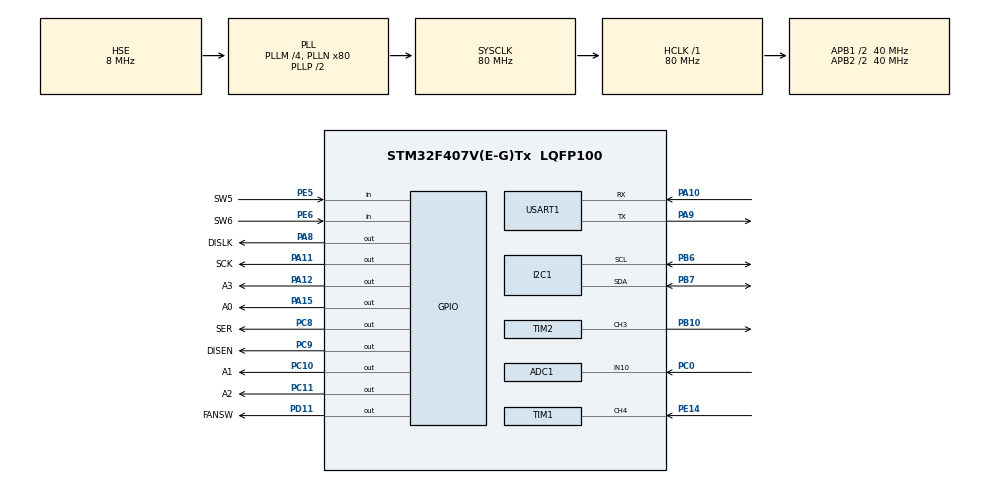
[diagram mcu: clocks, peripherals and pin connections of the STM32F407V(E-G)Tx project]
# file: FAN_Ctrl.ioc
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ADC1.Channel-1\#ChannelRegularConversion=ADC_CHANNEL_10
ADC1.ClockPrescaler=ADC_CLOCK_SYNC_PCLK_DIV2
ADC1.ContinuousConvMode=ENABLE
ADC1.NbrOfConversionFlag=1
ADC1.Rank-1\#ChannelRegularConversion=1
ADC1.Resolution=ADC_RESOLUTION_12B
ADC1.SamplingTime-1\#ChannelRegularConversion=ADC_SAMPLETIME_3CYCLES
ADC1.master=1
Mcu.Family=STM32F4
Mcu.Name=STM32F407V(E-G)Tx
Mcu.Package=LQFP100
NVIC.ADC_IRQn=true\:0\:0\:false\:false\:true\:true\:true\:true
NVIC.PriorityGroup=NVIC_PRIORITYGROUP_4
NVIC.TIM1_CC_IRQn=true\:0\:0\:false\:false\:true\:true\:true\:true
NVIC.TIM2_IRQn=true\:0\:0\:false\:false\:true\:true\:true\:true
NVIC.TIM6_DAC_IRQn=true\:0\:0\:false\:false\:true\:true\:true\:true
NVIC.USART1_IRQn=true\:0\:0\:false\:false\:true\:true\:true\:true
PA10.Mode=Asynchronous
PA10.Signal=USART1_RX
PA11.GPIO_Label=SCK
PA11.Signal=GPIO_Output
PA12.GPIO_Label=A3
PA12.Signal=GPIO_Output
PA13.Mode=Serial_Wire
PA13.Signal=SYS_JTMS-SWDIO
PA14.Mode=Serial_Wire
PA14.Signal=SYS_JTCK-SWCLK
PA15.GPIO_Label=A0
PA15.Signal=GPIO_Output
PA8.GPIO_Label=DISLK
PA8.Signal=GPIO_Output
PA9.Mode=Asynchronous
PA9.Signal=USART1_TX
PB10.Signal=S_TIM2_CH3
PB6.Mode=I2C
PB6.Signal=I2C1_SCL
PB7.Mode=I2C
PB7.Signal=I2C1_SDA
PC0.Signal=SharedAnalog_PC0
PC10.GPIO_Label=A1
PC10.Signal=GPIO_Output
PC11.GPIO_Label=A2
PC11.Signal=GPIO_Output
PC8.GPIO_Label=SER
PC8.Signal=GPIO_Output
PC9.GPIO_Label=DISEN
PC9.Signal=GPIO_Output
PD11.GPIO_Label=FANSW
PD11.Signal=GPIO_Output
PE14.GPIO_PuPd=GPIO_PULLUP
PE14.GPIO_Speed=GPIO_SPEED_FREQ_HIGH
PE14.Signal=S_TIM1_CH4
PE5.GPIO_Label=SW5
PE5.Signal=GPIO_Input
PE6.GPIO_Label=SW6
PE6.Signal=GPIO_Input
PH0-OSC_IN.Mode=HSE-External-Oscillator
PH0-OSC_IN.Signal=RCC_OSC_IN
PH1-OSC_OUT.Mode=HSE-External-Oscillator
PH1-OSC_OUT.Signal=RCC_OSC_OUT
ProjectManager.HeapSize=0x200
ProjectManager.StackSize=0x400
ProjectManager.TargetToolchain=MDK-ARM V5.32
RCC.48MHZClocksFreq_Value=40000000
RCC.AHBFreq_Value=80000000
RCC.APB1CLKDivider=RCC_HCLK_DIV2
RCC.APB1Freq_Value=40000000
RCC.APB1TimFreq_Value=80000000
RCC.APB2CLKDivider=RCC_HCLK_DIV2
RCC.APB2Freq_Value=40000000
RCC.APB2TimFreq_Value=80000000
RCC.CortexFreq_Value=80000000
RCC.EnbaleCSS=true
RCC.HCLKFreq_Value=80000000
RCC.HSE_VALUE=8000000
RCC.HSI_VALUE=16000000
RCC.LSE_VALUE=32768
RCC.PLLM=4
RCC.PLLN=80
RCC.PLLSourceVirtual=RCC_PLLSOURCE_HSE
RCC.SYSCLKFreq_VALUE=80000000
RCC.SYSCLKSource=RCC_SYSCLKSOURCE_PLLCLK
RCC.VCOOutputFreq_Value=160000000
SH.S_TIM1_CH4.0=TIM1_CH4,Input_Capture4_from_TI4
SH.S_TIM2_CH3.0=TIM2_CH3,PWM Generation3 CH3
SH.SharedAnalog_PC0.0=GPIO_Analog
SH.SharedAnalog_PC0.1=ADC1_IN10,IN10
TIM1.Channel-Input_Capture4_from_TI4=TIM_CHANNEL_4
TIM1.Prescaler=80-1
TIM2.Channel-PWM\ Generation3\ CH3=TIM_CHANNEL_3
TIM2.Period=100-1
TIM2.Prescaler=80-1
TIM2.Pulse-PWM\ Generation3\ CH3=50
TIM6.Period=1000-1
TIM6.Prescaler=80-1
USART1.VirtualMode=VM_ASYNC
VP_TIM1_VS_ClockSourceINT.Mode=Internal
VP_TIM2_VS_ClockSourceINT.Mode=Internal
VP_TIM6_VS_ClockSourceINT.Mode=Enable_Timer
board=custom

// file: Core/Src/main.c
/* USER CODE BEGIN Header */
/**
  ******************************************************************************
  * @file           : main.c
  * @brief          : Main program body
  ******************************************************************************
  * @attention
  *
  * Copyright (c) 2025 STMicroelectronics.
  * All rights reserved.
  *
  * This software is licensed under terms that can be found in the LICENSE file
  * in the root directory of this software component.
  * If no LICENSE file comes with this software, it is provided AS-IS.
  *
  ******************************************************************************
  */
/* USER CODE END Header */
#include "main.h"
#include "adc.h"
#include "i2c.h"
#include "tim.h"
#include "usart.h"
#include "gpio.h"

/* USER CODE BEGIN Includes */
#include "app.h"
/* USER CODE END Includes */

/* USER CODE BEGIN PTD */

/* USER CODE BEGIN PTD */

/* USER CODE END PTD */

void SystemClock_Config(void);

int main(void)
{

  /* MCU Configuration--------------------------------------------------------*/

  /* Reset of all peripherals, Initializes the Flash interface and the Systick. */
  HAL_Init();

  /* Configure the system clock */
  SystemClock_Config();

  /* Initialize all configured peripherals */
  MX_GPIO_Init();
  MX_TIM2_Init();
  MX_ADC1_Init();
  MX_USART1_UART_Init();
  MX_TIM1_Init();
  MX_I2C1_Init();
  MX_TIM6_Init();

  /* Infinite loop */
  while (1)
  {

    /* USER CODE BEGIN 3 */
		app_main();
  }
  /* USER CODE END 3 */
}

void SystemClock_Config(void)
{
  RCC_OscInitTypeDef RCC_OscInitStruct = {0};
  RCC_ClkInitTypeDef RCC_ClkInitStruct = {0};

  /** Configure the main internal regulator output voltage
  */
  __HAL_RCC_PWR_CLK_ENABLE();
  __HAL_PWR_VOLTAGESCALING_CONFIG(PWR_REGULATOR_VOLTAGE_SCALE1);

  /** Initializes the RCC Oscillators according to the specified parameters
  * in the RCC_OscInitTypeDef structure.
  */
  RCC_OscInitStruct.OscillatorType = RCC_OSCILLATORTYPE_HSE;
  RCC_OscInitStruct.HSEState = RCC_HSE_ON;
  RCC_OscInitStruct.PLL.PLLState = RCC_PLL_ON;
  RCC_OscInitStruct.PLL.PLLSource = RCC_PLLSOURCE_HSE;
  RCC_OscInitStruct.PLL.PLLM = 4;
  RCC_OscInitStruct.PLL.PLLN = 80;
  RCC_OscInitStruct.PLL.PLLP = RCC_PLLP_DIV2;
  RCC_OscInitStruct.PLL.PLLQ = 4;
  if (HAL_RCC_OscConfig(&RCC_OscInitStruct) != HAL_OK)
  {
    Error_Handler();
  }

  /** Initializes the CPU, AHB and APB buses clocks
  */
  RCC_ClkInitStruct.ClockType = RCC_CLOCKTYPE_HCLK|RCC_CLOCKTYPE_SYSCLK
                              |RCC_CLOCKTYPE_PCLK1|RCC_CLOCKTYPE_PCLK2;
  RCC_ClkInitStruct.SYSCLKSource = RCC_SYSCLKSOURCE_PLLCLK;
  RCC_ClkInitStruct.AHBCLKDivider = RCC_SYSCLK_DIV1;
  RCC_ClkInitStruct.APB1CLKDivider = RCC_HCLK_DIV2;
  RCC_ClkInitStruct.APB2CLKDivider = RCC_HCLK_DIV2;

  if (HAL_RCC_ClockConfig(&RCC_ClkInitStruct, FLASH_LATENCY_2) != HAL_OK)
  {
    Error_Handler();
  }

  /** Enables the Clock Security System
  */
  HAL_RCC_EnableCSS();
}

void Error_Handler(void)
{
  __disable_irq();
  while (1)
  {
  }
}
